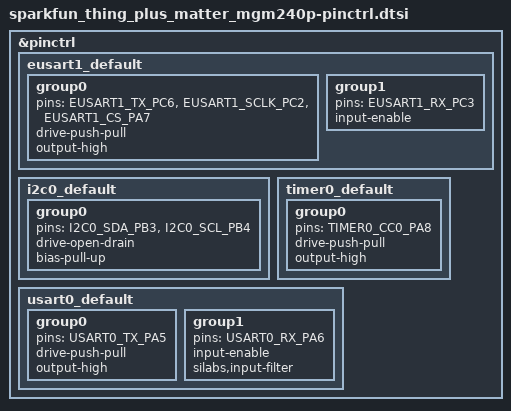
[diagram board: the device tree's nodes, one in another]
/*
 * Copyright (c) 2022 Silicon Labs
 *
 * SPDX-License-Identifier: Apache-2.0
 */

#include <zephyr/dt-bindings/pinctrl/silabs/xg24-pinctrl.h>

&pinctrl {
	eusart1_default: eusart1_default {
		group0 {
			pins = <EUSART1_TX_PC6>, <EUSART1_SCLK_PC2>, <EUSART1_CS_PA7>;
			drive-push-pull;
			output-high;
		};

		group1 {
			pins = <EUSART1_RX_PC3>;
			input-enable;
		};
	};

	i2c0_default: i2c0_default {
		group0 {
			pins = <I2C0_SDA_PB3>, <I2C0_SCL_PB4>;
			drive-open-drain;
			bias-pull-up;
		};
	};

	timer0_default: timer0_default {
		group0 {
			pins = <TIMER0_CC0_PA8>;
			drive-push-pull;
			output-high;
		};
	};

	/* configuration for uart0 device, default state */
	usart0_default: usart0_default {
		group0 {
			pins = <USART0_TX_PA5>;
			drive-push-pull;
			output-high;
		};

		group1 {
			pins = <USART0_RX_PA6>;
			input-enable;
			silabs,input-filter;
		};
	};
};
